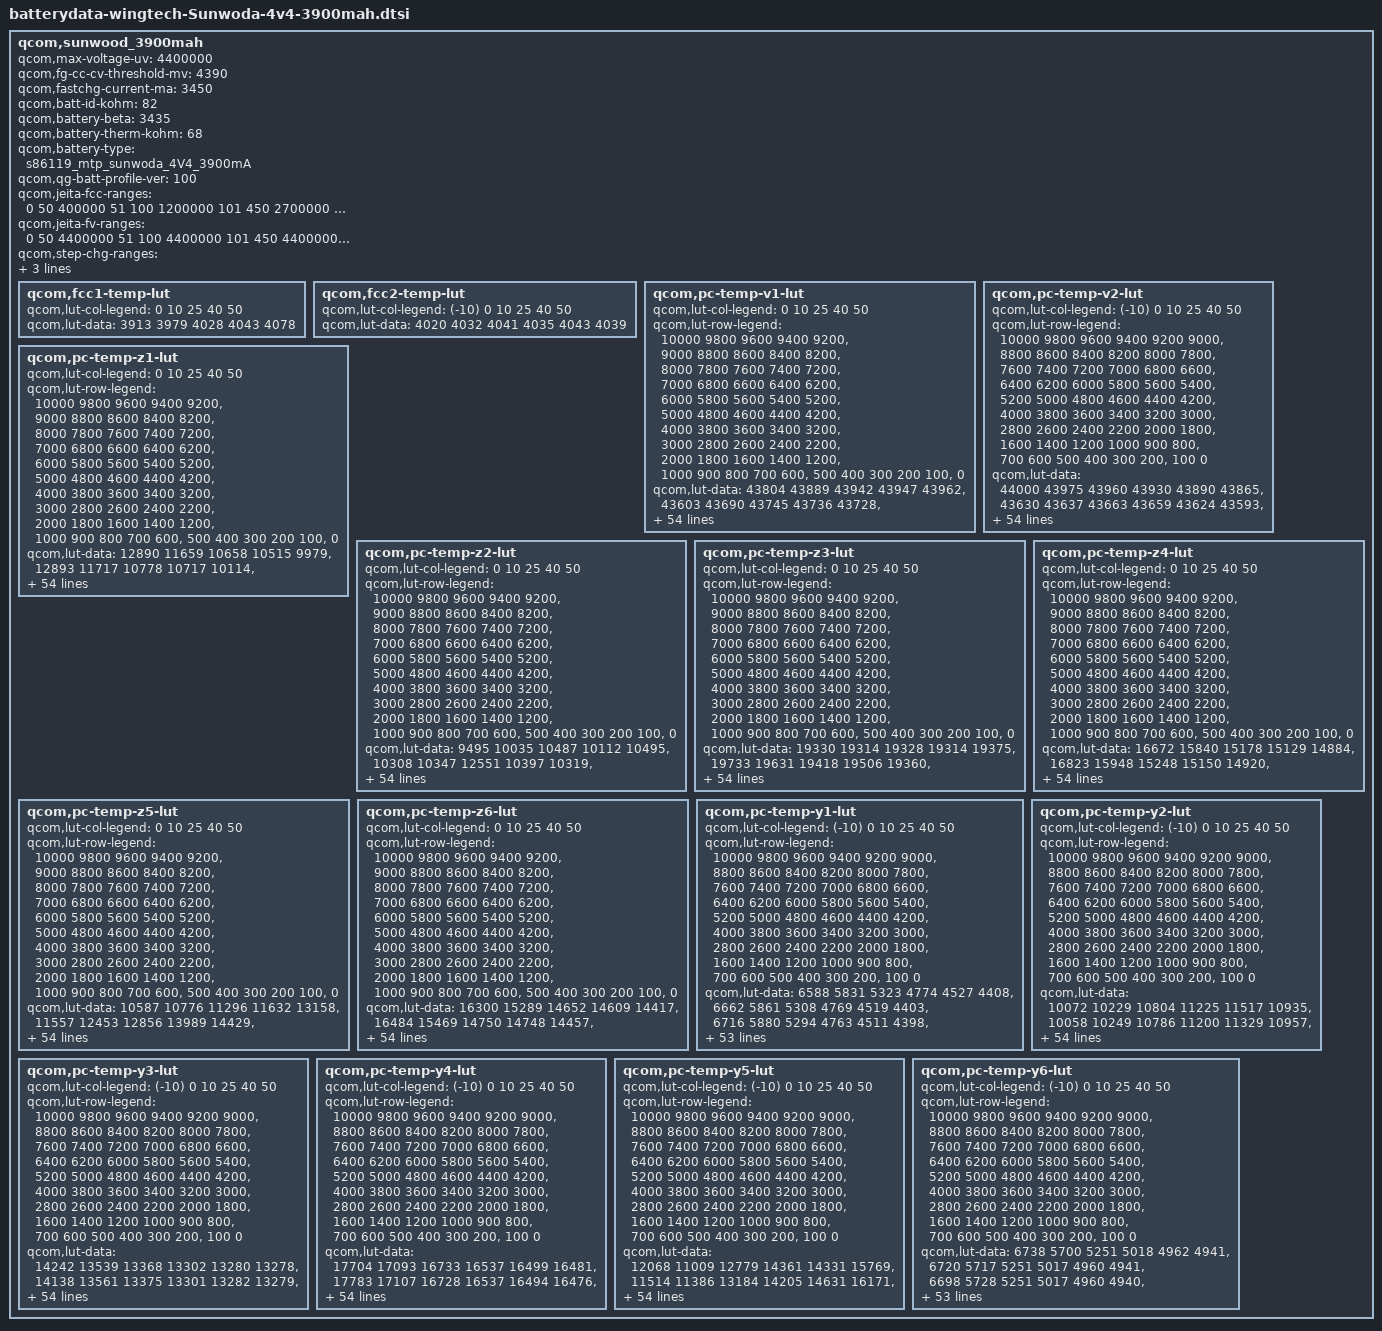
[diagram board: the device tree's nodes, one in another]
/* Copyright (c) 2018, The Linux Foundation. All rights reserved.
 *
 * This program is free software; you can redistribute it and/or modify
 * it under the terms of the GNU General Public License version 2 and
 * only version 2 as published by the Free Software Foundation.
 *
 * This program is distributed in the hope that it will be useful,
 * but WITHOUT ANY WARRANTY; without even the implied warranty of
 * MERCHANTABILITY or FITNESS FOR A PARTICULAR PURPOSE.  See the
 * GNU General Public License for more details.
 */

qcom,sunwood_3900mah {
	/* Sunwood_wConn_3450mAh_Fresh_averaged_MasterSlave_Feb7th2018 */
	qcom,max-voltage-uv = <4400000>;
	qcom,fg-cc-cv-threshold-mv = <4390>;
	qcom,fastchg-current-ma = <3450>;
	qcom,batt-id-kohm = <82>;
	qcom,battery-beta = <3435>;
	qcom,battery-therm-kohm = <68>;
	qcom,battery-type =
		"s86119_mtp_sunwoda_4V4_3900mA";
	qcom,qg-batt-profile-ver = <100>;
	//+Bug 439935 gudi.wt,MODIFIY,20190628,S86119AA1 set follow to batt spec
	qcom,jeita-fcc-ranges = <0   50  400000
				51   100 1200000
				101  450 2700000
				451  600 1400000>;
	qcom,jeita-fv-ranges = <0   50   4400000
				51  100  4400000
				101 450  4400000
				451 600  4100000>;
	qcom,step-chg-ranges = <3600000  4250000  2700000
				4251000  4300000  2700000
				4301000  4400000  2700000>;

	/* COOL = 5 DegC, WARM = 45 DegC */
qcom,jeita-soft-thresholds = <0x7001 0x0101>;
	/* COLD = 0 DegC, HOT = 55 DegC */
	qcom,jeita-hard-thresholds = <0x7001 0x0101>;
	//-Bug 439935 gudi.wt,MODIFIY,20190628,S86119AA1 set follow to batt spec
	qcom,fcc1-temp-lut {
		qcom,lut-col-legend = <0 10 25 40 50>;
		qcom,lut-data = <3913 3979 4028 4043 4078>;
	};

	qcom,fcc2-temp-lut {
		qcom,lut-col-legend = <(-10) 0 10 25 40 50>;
		qcom,lut-data = <4020 4032 4041 4035 4043 4039>;
	};

	qcom,pc-temp-v1-lut {
		qcom,lut-col-legend = <0 10 25 40 50>;
		qcom,lut-row-legend = <10000 9800 9600 9400 9200>,
			<9000 8800 8600 8400 8200>,
			<8000 7800 7600 7400 7200>,
			<7000 6800 6600 6400 6200>,
			<6000 5800 5600 5400 5200>,
			<5000 4800 4600 4400 4200>,
			<4000 3800 3600 3400 3200>,
			<3000 2800 2600 2400 2200>,
			<2000 1800 1600 1400 1200>,
			<1000 900 800 700 600>,
			<500 400 300 200 100>,
			<0>;
		qcom,lut-data = <43804 43889 43942 43947 43962>,
			<43603 43690 43745 43736 43728>,
			<43344 43446 43527 43514 43501>,
			<43096 43195 43287 43270 43277>,
			<42867 42953 43044 43027 43050>,
			<42638 42718 42807 42799 42820>,
			<42403 42486 42571 42573 42589>,
			<42165 42255 42337 42339 42357>,
			<41936 42026 42106 42096 42126>,
			<41715 41802 41877 41861 41894>,
			<41502 41581 41650 41639 41666>,
			<41306 41370 41428 41423 41440>,
			<41119 41178 41217 41205 41218>,
			<40914 40987 41016 40989 40997>,
			<40682 40772 40811 40780 40784>,
			<40450 40540 40597 40581 40586>,
			<40227 40326 40390 40386 40398>,
			<40015 40130 40199 40187 40216>,
			<39843 39953 40020 39994 40039>,
			<39705 39802 39855 39830 39866>,
			<39578 39666 39712 39700 39710>,
			<39452 39525 39549 39557 39548>,
			<39330 39382 39316 39346 39322>,
			<39212 39226 39064 39100 39035>,
			<39097 39025 38867 38911 38836>,
			<38986 38813 38700 38757 38718>,
			<38877 38665 38580 38638 38622>,
			<38770 38556 38504 38546 38534>,
			<38675 38473 38442 38468 38454>,
			<38585 38411 38378 38387 38371>,
			<38507 38362 38319 38309 38284>,
			<38436 38317 38262 38240 38203>,
			<38373 38276 38207 38178 38131>,
			<38323 38238 38154 38125 38064>,
			<38286 38202 38103 38085 38001>,
			<38249 38165 38054 38048 37942>,
			<38206 38126 38009 38000 37886>,
			<38160 38086 37970 37927 37837>,
			<38100 38030 37919 37850 37779>,
			<38024 37940 37829 37778 37685>,
			<37931 37828 37711 37694 37560>,
			<37806 37706 37587 37579 37430>,
			<37657 37565 37448 37427 37289>,
			<37492 37401 37292 37264 37137>,
			<37352 37255 37154 37116 37002>,
			<37253 37168 37071 37041 36923>,
			<37216 37139 37049 37035 36902>,
			<37192 37123 37034 36963 36889>,
			<37166 37102 37014 36925 36867>,
			<37111 37046 36947 36847 36771>,
			<36858 36781 36672 36591 36471>,
			<36406 36333 36224 36120 36014>,
			<35810 35740 35634 35577 35422>,
			<34996 34926 34823 34756 34610>,
			<33712 33646 33553 33486 33343>,
			<30000 30000 30000 30000 30000>;
	};

	qcom,pc-temp-v2-lut {
		qcom,lut-col-legend = <(-10) 0 10 25 40 50>;
		qcom,lut-row-legend = <10000 9800 9600 9400 9200 9000>,
			<8800 8600 8400 8200 8000 7800>,
			<7600 7400 7200 7000 6800 6600>,
			<6400 6200 6000 5800 5600 5400>,
			<5200 5000 4800 4600 4400 4200>,
			<4000 3800 3600 3400 3200 3000>,
			<2800 2600 2400 2200 2000 1800>,
			<1600 1400 1200 1000 900 800>,
			<700 600 500 400 300 200>,
			<100 0>;
		qcom,lut-data = <44000 43975 43960 43930 43890 43865>,
			<43630 43637 43663 43659 43624 43593>,
			<43288 43327 43384 43399 43369 43332>,
			<42974 43047 43124 43152 43125 43087>,
			<42683 42796 42881 42918 42894 42855>,
			<42428 42549 42642 42685 42663 42624>,
			<42222 42300 42403 42450 42429 42390>,
			<42020 42059 42167 42217 42195 42158>,
			<41752 41837 41939 41987 41964 41928>,
			<41441 41627 41716 41759 41735 41700>,
			<41234 41413 41493 41534 41510 41476>,
			<41127 41189 41271 41310 41289 41255>,
			<41011 40980 41059 41093 41073 41038>,
			<40771 40820 40875 40892 40866 40830>,
			<40431 40671 40698 40696 40663 40625>,
			<40110 40439 40485 40490 40459 40426>,
			<39785 40073 40232 40272 40254 40230>,
			<39519 39759 39987 40071 40063 40045>,
			<39344 39563 39760 39907 39896 39876>,
			<39197 39396 39546 39746 39732 39710>,
			<39039 39220 39352 39544 39546 39525>,
			<38876 39044 39171 39309 39344 39325>,
			<38721 38881 39001 39095 39141 39126>,
			<38565 38735 38837 38902 38928 38918>,
			<38427 38595 38687 38733 38741 38733>,
			<38324 38453 38556 38598 38605 38598>,
			<38240 38313 38437 38484 38493 38486>,
			<38166 38199 38329 38379 38388 38381>,
			<38098 38104 38230 38282 38291 38285>,
			<38034 38026 38137 38192 38204 38196>,
			<37974 37968 38048 38110 38133 38116>,
			<37916 37919 37967 38035 38066 38041>,
			<37856 37871 37896 37967 37992 37973>,
			<37794 37825 37834 37905 37913 37911>,
			<37733 37779 37783 37843 37831 37837>,
			<37674 37732 37744 37779 37743 37737>,
			<37614 37683 37706 37714 37654 37628>,
			<37552 37629 37665 37645 37565 37526>,
			<37487 37569 37620 37572 37476 37425>,
			<37424 37500 37558 37493 37406 37335>,
			<37364 37418 37468 37410 37351 37256>,
			<37300 37320 37363 37312 37258 37159>,
			<37228 37203 37239 37191 37134 37037>,
			<37150 37089 37086 37045 37041 36898>,
			<37052 36975 36951 36916 36850 36788>,
			<36930 36886 36891 36881 36819 36765>,
			<36870 36848 36867 36866 36824 36749>,
			<36798 36807 36843 36848 36826 36725>,
			<36714 36748 36806 36811 36786 36681>,
			<36563 36643 36704 36701 36691 36527>,
			<36321 36392 36416 36368 36357 36144>,
			<35904 35926 35908 35854 35853 35618>,
			<35280 35284 35225 35183 35177 34930>,
			<34376 34371 34278 34261 34288 33990>,
			<32889 32909 32949 32942 32763 32685>,
			<28713 29353 28070 28143 30475 28452>;
	};

	qcom,pc-temp-z1-lut {
		qcom,lut-col-legend = <0 10 25 40 50>;
		qcom,lut-row-legend = <10000 9800 9600 9400 9200>,
			<9000 8800 8600 8400 8200>,
			<8000 7800 7600 7400 7200>,
			<7000 6800 6600 6400 6200>,
			<6000 5800 5600 5400 5200>,
			<5000 4800 4600 4400 4200>,
			<4000 3800 3600 3400 3200>,
			<3000 2800 2600 2400 2200>,
			<2000 1800 1600 1400 1200>,
			<1000 900 800 700 600>,
			<500 400 300 200 100>,
			<0>;
		qcom,lut-data = <12890 11659 10658 10515 9979>,
			<12893 11717 10778 10717 10114>,
			<12969 11729 10779 10629 10129>,
			<13012 11750 10769 10666 10125>,
			<13011 11754 10760 10692 10125>,
			<12997 11754 10754 10656 10123>,
			<13003 11754 10748 10581 10121>,
			<13023 11748 10740 10528 10119>,
			<13026 11741 10730 10482 10116>,
			<13005 11742 10722 10464 10114>,
			<12985 11741 10719 10550 10120>,
			<12981 11738 10717 10657 10147>,
			<12979 11732 10715 10638 10159>,
			<12971 11725 10712 10540 10158>,
			<12930 11710 10712 10470 10156>,
			<12887 11682 10710 10424 10156>,
			<12865 11672 10708 10397 10156>,
			<12845 11670 10708 10448 10160>,
			<12838 11668 10707 10558 10180>,
			<12819 11664 10708 10583 10194>,
			<12799 11660 10709 10567 10192>,
			<12769 11659 10711 10556 10188>,
			<12720 11658 10715 10594 10180>,
			<12706 11658 10723 10648 10167>,
			<12708 11667 10730 10656 10163>,
			<12708 11682 10737 10657 10170>,
			<12701 11689 10742 10659 10177>,
			<12689 11695 10745 10664 10178>,
			<12686 11696 10747 10670 10178>,
			<12695 11690 10748 10615 10187>,
			<12702 11684 10749 10472 10235>,
			<12709 11680 10750 10433 10263>,
			<12719 11676 10756 10488 10260>,
			<12726 11674 10762 10533 10250>,
			<12735 11677 10766 10501 10231>,
			<12741 11683 10770 10444 10199>,
			<12742 11694 10777 10437 10179>,
			<12741 11715 10789 10457 10167>,
			<12741 11729 10797 10469 10161>,
			<12745 11737 10800 10446 10163>,
			<12753 11742 10802 10416 10166>,
			<12775 11744 10804 10487 10169>,
			<12795 11745 10807 10666 10171>,
			<12779 11735 10817 10678 10174>,
			<12752 11722 10827 10680 10178>,
			<12760 11713 10820 10541 10180>,
			<12745 11686 10811 10532 10179>,
			<12718 11690 10813 10562 10180>,
			<12706 11701 10818 10566 10180>,
			<12691 11724 10829 10557 10183>,
			<12721 11711 10837 10550 10188>,
			<12692 11732 10843 10671 10191>,
			<12739 11727 10854 10503 10199>,
			<12710 11743 10881 10618 10208>,
			<12710 11743 10881 10618 10208>,
			<12710 11743 10881 10618 10208>;
	};

	qcom,pc-temp-z2-lut {
		qcom,lut-col-legend = <0 10 25 40 50>;
		qcom,lut-row-legend = <10000 9800 9600 9400 9200>,
			<9000 8800 8600 8400 8200>,
			<8000 7800 7600 7400 7200>,
			<7000 6800 6600 6400 6200>,
			<6000 5800 5600 5400 5200>,
			<5000 4800 4600 4400 4200>,
			<4000 3800 3600 3400 3200>,
			<3000 2800 2600 2400 2200>,
			<2000 1800 1600 1400 1200>,
			<1000 900 800 700 600>,
			<500 400 300 200 100>,
			<0>;
		qcom,lut-data = <9495 10035 10487 10112 10495>,
			<10308 10347 12551 10397 10319>,
			<10080 10276 11212 10496 10600>,
			<10128 10183 10600 10416 10618>,
			<10293 10156 10377 10340 10538>,
			<10408 10148 10347 10325 10492>,
			<10358 10145 10323 10318 10466>,
			<10203 10156 10327 10334 10450>,
			<10131 10170 10357 10406 10442>,
			<10119 10169 10377 10451 10438>,
			<10115 10161 10382 10419 10448>,
			<10121 10157 10386 10377 10477>,
			<10134 10174 10395 10396 10494>,
			<10141 10194 10412 10461 10510>,
			<10143 10193 10427 10486 10516>,
			<10144 10182 10439 10440 10477>,
			<10142 10180 10452 10394 10416>,
			<10138 10220 10507 10394 10400>,
			<10144 10260 10589 10409 10407>,
			<10191 10264 10590 10440 10412>,
			<10241 10262 10508 10508 10379>,
			<10269 10261 10465 10561 10343>,
			<10290 10265 10495 10530 10444>,
			<10293 10269 10537 10475 10707>,
			<10282 10277 10540 10479 10791>,
			<10270 10286 10516 10485 10626>,
			<10263 10291 10499 10474 10468>,
			<10257 10296 10486 10456 10426>,
			<10254 10298 10477 10451 10406>,
			<10251 10298 10494 10523 10465>,
			<10250 10298 10539 10670 10678>,
			<10255 10301 10557 10715 10789>,
			<10264 10310 10553 10638 10696>,
			<10270 10318 10545 10557 10582>,
			<10274 10325 10534 10537 10565>,
			<10278 10331 10519 10532 10573>,
			<10282 10339 10517 10546 10566>,
			<10287 10348 10520 10579 10535>,
			<10296 10357 10525 10618 10518>,
			<10321 10365 10563 10665 10629>,
			<10354 10376 10611 10717 10805>,
			<10388 10393 10621 10850 10836>,
			<10437 10421 10624 11094 10837>,
			<10583 10469 10636 10972 10791>,
			<10449 10653 10719 10888 10648>,
			<10080 11048 10884 11107 10580>,
			<10064 11106 10904 11077 10579>,
			<10090 10835 10932 10730 10535>,
			<9980 10847 10934 10611 10593>,
			<10096 11117 11002 10666 10674>,
			<10053 11065 11156 10696 10571>,
			<10041 10878 11080 10799 10444>,
			<9862 10677 11253 11604 10412>,
			<9733 10569 11037 10970 10252>,
			<9733 10569 11037 10970 10252>,
			<9733 10569 11037 10970 10252>;
	};

	qcom,pc-temp-z3-lut {
		qcom,lut-col-legend = <0 10 25 40 50>;
		qcom,lut-row-legend = <10000 9800 9600 9400 9200>,
			<9000 8800 8600 8400 8200>,
			<8000 7800 7600 7400 7200>,
			<7000 6800 6600 6400 6200>,
			<6000 5800 5600 5400 5200>,
			<5000 4800 4600 4400 4200>,
			<4000 3800 3600 3400 3200>,
			<3000 2800 2600 2400 2200>,
			<2000 1800 1600 1400 1200>,
			<1000 900 800 700 600>,
			<500 400 300 200 100>,
			<0>;
		qcom,lut-data = <19330 19314 19328 19314 19375>,
			<19733 19631 19418 19506 19360>,
			<19955 19713 19488 19511 19420>,
			<20034 19832 19564 19537 19460>,
			<20032 19858 19606 19551 19473>,
			<20013 19862 19613 19561 19474>,
			<20011 19862 19617 19567 19459>,
			<20014 19859 19613 19564 19443>,
			<20019 19854 19593 19547 19432>,
			<20025 19849 19575 19533 19423>,
			<20030 19843 19561 19554 19421>,
			<20024 19835 19546 19581 19422>,
			<20011 19811 19531 19567 19425>,
			<20006 19790 19516 19517 19433>,
			<20013 19792 19512 19485 19438>,
			<20023 19804 19512 19464 19423>,
			<20047 19805 19513 19449 19392>,
			<20083 19759 19514 19460 19382>,
			<20083 19714 19514 19487 19381>,
			<20013 19712 19511 19486 19382>,
			<19955 19716 19498 19437 19374>,
			<19957 19720 19494 19404 19365>,
			<19966 19726 19515 19442 19370>,
			<19976 19735 19542 19502 19390>,
			<19994 19763 19545 19508 19397>,
			<20013 19800 19538 19488 19384>,
			<20030 19806 19529 19472 19367>,
			<20046 19800 19516 19463 19351>,
			<20053 19793 19503 19457 19334>,
			<20061 19786 19496 19451 19335>,
			<20064 19776 19490 19447 19361>,
			<20062 19765 19490 19448 19382>,
			<20058 19752 19499 19453 19394>,
			<20048 19740 19508 19455 19402>,
			<20016 19732 19513 19446 19399>,
			<19980 19724 19517 19431 19388>,
			<19959 19717 19516 19427 19378>,
			<19940 19710 19506 19430 19361>,
			<19915 19704 19497 19429 19350>,
			<19879 19700 19493 19408 19354>,
			<19840 19694 19489 19380 19361>,
			<19804 19681 19485 19372 19366>,
			<19762 19656 19482 19369 19371>,
			<19701 19631 19472 19357 19368>,
			<19503 19569 19446 19337 19354>,
			<19347 19446 19408 19324 19341>,
			<19351 19427 19400 19323 19341>,
			<19343 19337 19377 19362 19332>,
			<19337 19325 19386 19366 19320>,
			<19339 19334 19365 19353 19321>,
			<19346 19362 19351 19356 19325>,
			<19352 19340 19326 19319 19334>,
			<19364 19339 19325 19290 19337>,
			<19363 19338 19320 19429 19344>,
			<19363 19338 19320 19429 19344>,
			<19363 19338 19320 19429 19344>;
	};

	qcom,pc-temp-z4-lut {
		qcom,lut-col-legend = <0 10 25 40 50>;
		qcom,lut-row-legend = <10000 9800 9600 9400 9200>,
			<9000 8800 8600 8400 8200>,
			<8000 7800 7600 7400 7200>,
			<7000 6800 6600 6400 6200>,
			<6000 5800 5600 5400 5200>,
			<5000 4800 4600 4400 4200>,
			<4000 3800 3600 3400 3200>,
			<3000 2800 2600 2400 2200>,
			<2000 1800 1600 1400 1200>,
			<1000 900 800 700 600>,
			<500 400 300 200 100>,
			<0>;
		qcom,lut-data = <16672 15840 15178 15129 14884>,
			<16823 15948 15248 15150 14920>,
			<16887 15946 15372 15199 14921>,
			<16873 15784 15271 15211 14952>,
			<16669 15643 15156 15200 14889>,
			<16420 15505 15085 15117 14845>,
			<16252 15387 15025 14981 14817>,
			<16105 15293 14971 14893 14799>,
			<15977 15215 14918 14829 14791>,
			<15864 15155 14884 14800 14785>,
			<15765 15107 14870 14795 14782>,
			<15676 15064 14859 14790 14783>,
			<15597 15022 14847 14782 14782>,
			<15545 14983 14836 14770 14755>,
			<15514 14942 14824 14763 14728>,
			<15485 14901 14814 14774 14727>,
			<15441 14892 14802 14784 14732>,
			<15394 14925 14778 14773 14729>,
			<15380 14955 14750 14747 14715>,
			<15391 14937 14739 14741 14706>,
			<15398 14888 14730 14759 14709>,
			<15355 14855 14731 14771 14720>,
			<15266 14831 14762 14783 14751>,
			<15193 14819 14812 14814 14819>,
			<15129 14834 14853 14840 14854>,
			<15075 14865 14894 14883 14866>,
			<15036 14883 14909 14902 14872>,
			<15003 14895 14901 14900 14876>,
			<14982 14900 14887 14894 14876>,
			<14964 14894 14873 14869 14865>,
			<14950 14882 14856 14815 14830>,
			<14934 14871 14835 14786 14794>,
			<14919 14860 14805 14770 14759>,
			<14916 14850 14779 14760 14730>,
			<14920 14839 14760 14752 14725>,
			<14923 14828 14747 14740 14723>,
			<14920 14818 14744 14736 14723>,
			<14914 14807 14743 14736 14724>,
			<14914 14803 14743 14739 14727>,
			<14920 14801 14755 14750 14733>,
			<14928 14801 14769 14767 14741>,
			<14939 14802 14768 14802 14739>,
			<14948 14803 14760 14863 14730>,
			<14953 14799 14760 14867 14733>,
			<14999 14787 14753 14859 14737>,
			<15054 14806 14721 14770 14705>,
			<15047 14821 14718 14737 14690>,
			<15048 14916 14725 14721 14676>,
			<15049 14924 14705 14714 14665>,
			<15038 14906 14733 14731 14675>,
			<15033 14891 14777 14738 14708>,
			<15042 14924 14815 14841 14704>,
			<15048 14934 14820 14789 14704>,
			<15062 14941 14833 14669 14699>,
			<15062 14941 14833 14669 14699>,
			<15062 14941 14833 14669 14699>;
	};

	qcom,pc-temp-z5-lut {
		qcom,lut-col-legend = <0 10 25 40 50>;
		qcom,lut-row-legend = <10000 9800 9600 9400 9200>,
			<9000 8800 8600 8400 8200>,
			<8000 7800 7600 7400 7200>,
			<7000 6800 6600 6400 6200>,
			<6000 5800 5600 5400 5200>,
			<5000 4800 4600 4400 4200>,
			<4000 3800 3600 3400 3200>,
			<3000 2800 2600 2400 2200>,
			<2000 1800 1600 1400 1200>,
			<1000 900 800 700 600>,
			<500 400 300 200 100>,
			<0>;
		qcom,lut-data = <10587 10776 11296 11632 13158>,
			<11557 12453 12856 13989 14429>,
			<12201 12973 13438 15014 17050>,
			<12487 13849 14567 15157 17471>,
			<12525 14217 15511 15379 18469>,
			<12534 14362 15901 15600 18738>,
			<12704 14527 16184 15862 18715>,
			<13051 14810 16537 16867 18670>,
			<13332 15152 17055 21283 18429>,
			<13539 15474 17393 23666 18072>,
			<13715 15787 17487 21718 17863>,
			<13867 16092 17495 19349 17621>,
			<13996 16342 17450 20053 17750>,
			<14077 16665 17373 23155 25015>,
			<14173 17918 17376 24243 32470>,
			<14300 20371 17854 20486 29087>,
			<14712 21073 18514 16914 20734>,
			<15350 18668 19963 19535 18814>,
			<15441 16423 22031 25525 20978>,
			<14758 16703 22404 26587 22519>,
			<14203 17876 22860 21327 20979>,
			<14418 19355 24567 18065 19028>,
			<15033 21472 35943 23132 22881>,
			<15771 24683 50303 31360 33796>,
			<16854 33966 50583 32438 37412>,
			<18232 46013 43368 27964 30081>,
			<20180 47756 36443 23640 21992>,
			<22509 43906 30699 20529 18120>,
			<23871 39708 26129 18242 15346>,
			<25269 36373 23520 19241 15037>,
			<26413 33276 21601 22353 16000>,
			<27401 30856 21260 23599 17363>,
			<28522 28766 22556 24391 20644>,
			<28422 27585 24427 25228 24256>,
			<25776 26947 27434 24973 25532>,
			<23402 26556 30873 24241 26291>,
			<22725 26550 31260 25296 26401>,
			<22263 26644 29870 30990 24057>,
			<21666 26835 28435 33713 22098>,
			<20621 27774 27362 27413 21476>,
			<19580 28617 26405 19285 20620>,
			<18808 27257 25714 17079 20806>,
			<18091 24449 25107 16239 21335>,
			<17251 23644 23197 16037 20291>,
			<14739 22445 21902 16069 18157>,
			<12709 17021 21067 16240 18025>,
			<12736 15882 19560 15299 18625>,
			<12561 12929 16849 22800 18252>,
			<12459 12534 17958 24477 18272>,
			<12554 12860 15963 22339 17537>,
			<12792 13701 14575 19064 14623>,
			<12731 12904 13162 13811 14684>,
			<12687 12704 12902 12151 14462>,
			<12490 12547 12555 65535 14658>,
			<12490 12547 12555 65535 14658>,
			<12490 12547 12555 65535 14658>;
	};

	qcom,pc-temp-z6-lut {
		qcom,lut-col-legend = <0 10 25 40 50>;
		qcom,lut-row-legend = <10000 9800 9600 9400 9200>,
			<9000 8800 8600 8400 8200>,
			<8000 7800 7600 7400 7200>,
			<7000 6800 6600 6400 6200>,
			<6000 5800 5600 5400 5200>,
			<5000 4800 4600 4400 4200>,
			<4000 3800 3600 3400 3200>,
			<3000 2800 2600 2400 2200>,
			<2000 1800 1600 1400 1200>,
			<1000 900 800 700 600>,
			<500 400 300 200 100>,
			<0>;
		qcom,lut-data = <16300 15289 14652 14609 14417>,
			<16484 15469 14750 14748 14457>,
			<16576 15476 14832 14746 14490>,
			<16589 15462 14820 14771 14520>,
			<16480 15433 14801 14783 14504>,
			<16337 15359 14779 14745 14487>,
			<16239 15289 14748 14674 14467>,
			<16151 15238 14718 14621 14451>,
			<16079 15196 14684 14576 14440>,
			<16021 15163 14658 14554 14433>,
			<15971 15137 14643 14579 14431>,
			<15919 15110 14631 14611 14438>,
			<15866 15075 14618 14596 14439>,
			<15829 15043 14605 14544 14432>,
			<15803 15024 14597 14513 14422>,
			<15784 15009 14592 14499 14411>,
			<15774 14999 14587 14491 14397>,
			<15765 14989 14577 14499 14391>,
			<15751 14979 14566 14522 14387>,
			<15722 14965 14557 14523 14385>,
			<15687 14948 14548 14502 14384>,
			<15648 14938 14544 14488 14382>,
			<15606 14933 14568 14519 14395>,
			<15583 14930 14607 14576 14435>,
			<15572 14949 14626 14594 14450>,
			<15562 14984 14640 14600 14448>,
			<15550 14997 14644 14601 14445>,
			<15539 15001 14636 14598 14439>,
			<15535 15003 14623 14592 14430>,
			<15535 14999 14613 14568 14427>,
			<15535 14990 14604 14513 14433>,
			<15528 14981 14596 14494 14435>,
			<15517 14967 14588 14500 14427>,
			<15505 14956 14582 14505 14416>,
			<15493 14949 14579 14491 14406>,
			<15482 14943 14576 14467 14396>,
			<15475 14936 14573 14462 14387>,
			<15468 14928 14570 14466 14375>,
			<15460 14925 14568 14468 14369>,
			<15450 14927 14571 14458 14374>,
			<15439 14929 14575 14446 14382>,
			<15429 14926 14575 14470 14383>,
			<15416 14918 14571 14533 14383>,
			<15389 14908 14568 14533 14382>,
			<15306 14872 14555 14519 14378>,
			<15249 14823 14522 14441 14357>,
			<15242 14816 14513 14425 14351>,
			<15242 14812 14506 14444 14340>,
			<15245 14814 14502 14442 14328>,
			<15241 14810 14506 14443 14334>,
			<15255 14819 14520 14446 14352>,
			<15258 14831 14525 14499 14357>,
			<15284 14845 14529 14424 14360>,
			<15296 14857 14540 14471 14364>,
			<15296 14857 14540 14471 14364>,
			<15296 14857 14540 14471 14364>;
	};

	qcom,pc-temp-y1-lut {
		qcom,lut-col-legend = <(-10) 0 10 25 40 50>;
		qcom,lut-row-legend = <10000 9800 9600 9400 9200 9000>,
			<8800 8600 8400 8200 8000 7800>,
			<7600 7400 7200 7000 6800 6600>,
			<6400 6200 6000 5800 5600 5400>,
			<5200 5000 4800 4600 4400 4200>,
			<4000 3800 3600 3400 3200 3000>,
			<2800 2600 2400 2200 2000 1800>,
			<1600 1400 1200 1000 900 800>,
			<700 600 500 400 300 200>,
			<100 0>;
		qcom,lut-data = <6588 5831 5323 4774 4527 4408>,
			<6662 5861 5308 4769 4519 4403>,
			<6716 5880 5294 4763 4511 4398>,
			<6751 5889 5283 4758 4505 4394>,
			<6773 5891 5276 4752 4500 4390>,
			<6783 5887 5275 4747 4497 4387>,
			<6770 5869 5279 4742 4496 4384>,
			<6752 5851 5284 4737 4496 4382>,
			<6751 5862 5276 4732 4492 4382>,
			<6751 5893 5256 4727 4485 4381>,
			<6752 5902 5246 4725 4480 4381>,
			<6756 5890 5242 4722 4478 4381>,
			<6761 5879 5240 4721 4476 4381>,
			<6765 5884 5236 4719 4475 4380>,
			<6768 5898 5231 4717 4476 4378>,
			<6770 5895 5231 4717 4474 4378>,
			<6778 5876 5238 4719 4471 4378>,
			<6779 5865 5242 4720 4469 4378>,
			<6767 5874 5241 4718 4469 4379>,
			<6754 5889 5238 4715 4470 4380>,
			<6753 5899 5243 4718 4470 4380>,
			<6758 5908 5258 4729 4470 4380>,
			<6760 5910 5263 4734 4470 4380>,
			<6740 5896 5264 4733 4472 4383>,
			<6716 5881 5266 4732 4473 4385>,
			<6712 5874 5266 4734 4479 4386>,
			<6716 5868 5265 4739 4491 4387>,
			<6720 5864 5265 4744 4502 4388>,
			<6722 5859 5265 4750 4515 4390>,
			<6724 5856 5267 4755 4522 4392>,
			<6724 5866 5271 4757 4522 4393>,
			<6724 5882 5278 4759 4521 4393>,
			<6723 5883 5287 4764 4518 4395>,
			<6712 5882 5296 4772 4515 4398>,
			<6698 5880 5299 4777 4518 4402>,
			<6673 5870 5290 4779 4559 4406>,
			<6644 5861 5281 4781 4601 4410>,
			<6646 5866 5286 4788 4616 4412>,
			<6665 5876 5298 4799 4627 4414>,
			<6687 5873 5304 4801 4620 4415>,
			<6715 5844 5300 4796 4574 4415>,
			<6729 5839 5302 4798 4570 4417>,
			<6700 5863 5307 4809 4595 4420>,
			<6674 5893 5293 4812 4614 4421>,
			<6685 5884 5304 4813 4654 4422>,
			<6732 5838 5306 4814 4648 4424>,
			<6760 5868 5314 4822 4645 4426>,
			<6726 5861 5311 4815 4674 4426>,
			<6690 5858 5298 4818 4687 4429>,
			<6706 5849 5296 4825 4681 4426>,
			<6718 5881 5301 4827 4642 4426>,
			<6701 5859 5318 4828 4670 4431>,
			<6763 5856 5347 4840 4676 4434>,
			<6900 5903 5352 4853 4687 4440>,
			<6900 5903 5352 4853 4687 4440>,
			<6900 5903 5352 4853 4687 4440>;
	};

	qcom,pc-temp-y2-lut {
		qcom,lut-col-legend = <(-10) 0 10 25 40 50>;
		qcom,lut-row-legend = <10000 9800 9600 9400 9200 9000>,
			<8800 8600 8400 8200 8000 7800>,
			<7600 7400 7200 7000 6800 6600>,
			<6400 6200 6000 5800 5600 5400>,
			<5200 5000 4800 4600 4400 4200>,
			<4000 3800 3600 3400 3200 3000>,
			<2800 2600 2400 2200 2000 1800>,
			<1600 1400 1200 1000 900 800>,
			<700 600 500 400 300 200>,
			<100 0>;
		qcom,lut-data = <10072 10229 10804 11225 11517 10935>,
			<10058 10249 10786 11200 11329 10957>,
			<10059 10268 10766 11166 11164 10957>,
			<10072 10286 10746 11132 11035 10945>,
			<10093 10304 10730 11104 10953 10932>,
			<10120 10321 10722 11092 10932 10927>,
			<10152 10340 10718 11087 10981 10907>,
			<10197 10354 10716 11087 11040 10886>,
			<10310 10348 10720 11096 11071 10886>,
			<10499 10330 10730 11110 11110 10892>,
			<10555 10338 10736 11117 11138 10915>,
			<10495 10486 10740 11125 11161 10998>,
			<10444 10617 10744 11131 11175 11067>,
			<10499 10635 10758 11124 11178 11072>,
			<10607 10640 10784 11115 11184 11061>,
			<10546 10643 10816 11127 11206 11075>,
			<10022 10651 10867 11172 11263 11154>,
			<9681 10665 10895 11208 11319 11208>,
			<9676 10713 10900 11234 11373 11251>,
			<9673 10787 10903 11254 11422 11316>,
			<9671 10854 10918 11240 11451 11409>,
			<9670 10924 10953 11194 11475 11539>,
			<9668 10965 10990 11179 11472 11565>,
			<9666 10997 11029 11215 11370 11350>,
			<9665 11016 11069 11261 11285 11160>,
			<9664 11007 11110 11293 11286 11179>,
			<9663 10986 11149 11326 11292 11229>,
			<9662 10986 11177 11349 11344 11245>,
			<9661 11029 11199 11386 11569 11228>,
			<9661 11058 11208 11409 11698 11222>,
			<9660 10836 11204 11398 11575 11273>,
			<9660 10458 11195 11382 11422 11350>,
			<9659 10256 11190 11380 11488 11408>,
			<9659 9881 11187 11391 11716 11472>,
			<9658 9705 11179 11392 11778 11489>,
			<9658 9692 11139 11371 11440 11330>,
			<9658 9684 11088 11348 11115 11172>,
			<9657 9677 11050 11343 11087 11188>,
			<9657 9671 11016 11346 11111 11237>,
			<9657 9667 10986 11334 11253 11245>,
			<9657 9665 10962 11257 11890 11219>,
			<9656 9663 10931 11237 11755 11267>,
			<9656 9661 10884 11319 11191 11369>,
			<9656 9660 10818 11242 11245 11115>,
			<9656 9661 10778 11258 11083 11051>,
			<9656 9659 10718 11222 10934 11008>,
			<9656 9658 10675 11211 10935 10968>,
			<9656 9657 10622 11205 11004 11005>,
			<9655 9656 10617 11177 10910 10942>,
			<9655 9656 10579 11072 10987 10874>,
			<9655 9655 10522 11057 10955 10901>,
			<9654 9655 10278 10998 11030 10904>,
			<9653 9654 9828 10976 10842 10772>,
			<9651 9653 9692 10834 10771 10651>,
			<9651 9653 9692 10834 10771 10651>,
			<9651 9653 9692 10834 10771 10651>;
	};

	qcom,pc-temp-y3-lut {
		qcom,lut-col-legend = <(-10) 0 10 25 40 50>;
		qcom,lut-row-legend = <10000 9800 9600 9400 9200 9000>,
			<8800 8600 8400 8200 8000 7800>,
			<7600 7400 7200 7000 6800 6600>,
			<6400 6200 6000 5800 5600 5400>,
			<5200 5000 4800 4600 4400 4200>,
			<4000 3800 3600 3400 3200 3000>,
			<2800 2600 2400 2200 2000 1800>,
			<1600 1400 1200 1000 900 800>,
			<700 600 500 400 300 200>,
			<100 0>;
		qcom,lut-data = <14242 13539 13368 13302 13280 13278>,
			<14138 13561 13375 13301 13282 13279>,
			<14056 13579 13381 13301 13283 13280>,
			<13998 13591 13386 13302 13285 13281>,
			<13963 13597 13389 13302 13286 13282>,
			<13955 13599 13390 13303 13287 13283>,
			<13986 13592 13388 13305 13288 13284>,
			<14021 13584 13386 13307 13289 13286>,
			<13970 13593 13387 13308 13289 13286>,
			<13814 13619 13390 13309 13290 13287>,
			<13722 13625 13391 13310 13291 13288>,
			<13678 13600 13390 13311 13296 13288>,
			<13657 13574 13389 13312 13299 13289>,
			<13676 13557 13396 13312 13298 13290>,
			<13713 13540 13406 13312 13297 13291>,
			<13704 13535 13408 13312 13297 13292>,
			<13596 13534 13406 13314 13299 13292>,
			<13527 13532 13404 13316 13300 13293>,
			<13527 13513 13397 13322 13298 13292>,
			<13528 13485 13389 13327 13296 13291>,
			<13531 13466 13383 13326 13296 13291>,
			<13539 13450 13377 13322 13296 13290>,
			<13542 13436 13371 13317 13296 13289>,
			<13530 13423 13363 13309 13290 13284>,
			<13518 13412 13356 13303 13284 13279>,
			<13523 13405 13353 13302 13284 13279>,
			<13541 13401 13350 13301 13286 13279>,
			<13560 13390 13347 13300 13288 13279>,
			<13579 13365 13344 13301 13294 13278>,
			<13602 13349 13343 13301 13297 13277>,
			<13632 13352 13345 13302 13292 13277>,
			<13668 13360 13346 13304 13286 13278>,
			<13701 13369 13344 13306 13294 13279>,
			<13730 13383 13337 13308 13318 13281>,
			<13764 13398 13334 13309 13326 13282>,
			<13810 13413 13340 13310 13315 13280>,
			<13861 13429 13347 13310 13302 13278>,
			<13914 13447 13354 13309 13296 13277>,
			<13970 13469 13361 13306 13292 13277>,
			<14033 13494 13363 13304 13296 13277>,
			<14111 13525 13360 13302 13318 13277>,
			<14172 13560 13358 13302 13321 13279>,
			<14209 13605 13357 13304 13306 13281>,
			<14238 13649 13348 13302 13282 13278>,
			<14099 13604 13332 13296 13287 13277>,
			<14211 13703 13342 13302 13298 13287>,
			<14306 13779 13348 13303 13298 13286>,
			<14372 13840 13361 13308 13285 13289>,
			<14460 13940 13377 13319 13285 13293>,
			<14548 14035 13392 13325 13283 13291>,
			<14674 14132 13395 13307 13299 13288>,
			<14787 14255 13401 13312 13288 13291>,
			<15137 14441 13440 13326 13303 13295>,
			<15969 14723 13509 13342 13296 13300>,
			<15969 14723 13509 13342 13296 13300>,
			<15969 14723 13509 13342 13296 13300>;
	};

	qcom,pc-temp-y4-lut {
		qcom,lut-col-legend = <(-10) 0 10 25 40 50>;
		qcom,lut-row-legend = <10000 9800 9600 9400 9200 9000>,
			<8800 8600 8400 8200 8000 7800>,
			<7600 7400 7200 7000 6800 6600>,
			<6400 6200 6000 5800 5600 5400>,
			<5200 5000 4800 4600 4400 4200>,
			<4000 3800 3600 3400 3200 3000>,
			<2800 2600 2400 2200 2000 1800>,
			<1600 1400 1200 1000 900 800>,
			<700 600 500 400 300 200>,
			<100 0>;
		qcom,lut-data = <17704 17093 16733 16537 16499 16481>,
			<17783 17107 16728 16537 16494 16476>,
			<17830 17119 16725 16539 16491 16473>,
			<17854 17129 16724 16541 16490 16470>,
			<17862 17134 16725 16544 16490 16470>,
			<17859 17136 16726 16546 16491 16469>,
			<17707 17134 16730 16548 16494 16471>,
			<17537 17129 16735 16552 16497 16474>,
			<17566 17109 16739 16558 16503 16477>,
			<17702 17068 16745 16568 16509 16482>,
			<17833 17059 16752 16578 16514 16487>,
			<17978 17107 16760 16589 16516 16494>,
			<18068 17173 16772 16602 16519 16501>,
			<17854 17265 16809 16621 16530 16509>,
			<17441 17368 16855 16646 16548 16517>,
			<17361 17335 16861 16667 16562 16526>,
			<17449 17063 16846 16686 16572 16536>,
			<17506 16904 16823 16702 16585 16548>,
			<17476 16913 16773 16717 16614 16570>,
			<17413 16923 16716 16728 16639 16590>,
			<17344 16919 16685 16708 16636 16589>,
			<17257 16897 16663 16635 16617 16580>,
			<17192 16875 16649 16580 16589 16565>,
			<17147 16857 16639 16543 16532 16518>,
			<17118 16835 16633 16522 16491 16482>,
			<17108 16790 16631 16523 16493 16482>,
			<17102 16731 16630 16526 16498 16483>,
			<17099 16720 16631 16531 16498 16487>,
			<17098 16748 16633 16538 16489 16499>,
			<17096 16779 16634 16547 16487 16512>,
			<17093 16799 16621 16556 16531 16525>,
			<17090 16816 16604 16567 16583 16537>,
			<17091 16835 16606 16577 16570 16550>,
			<17097 16858 16622 16587 16507 16562>,
			<17102 16874 16636 16591 16484 16566>,
			<17107 16883 16646 16584 16478 16546>,
			<17113 16891 16655 16575 16471 16521>,
			<17126 16901 16667 16565 16462 16505>,
			<17152 16911 16680 16554 16452 16492>,
			<17172 16914 16683 16551 16450 16490>,
			<17192 16905 16682 16557 16456 16496>,
			<17210 16895 16682 16558 16457 16496>,
			<17231 16884 16679 16553 16459 16488>,
			<17206 16863 16665 16545 16576 16486>,
			<17073 16838 16654 16520 16442 16464>,
			<17094 16846 16663 16538 16449 16477>,
			<17115 16869 16683 16563 16491 16497>,
			<17136 16896 16710 16584 16569 16518>,
			<17143 16942 16743 16602 16595 16541>,
			<17156 16972 16764 16607 16641 16529>,
			<17140 16973 16749 16591 16545 16484>,
			<17122 16962 16750 16578 16575 16483>,
			<17255 16979 16811 16579 16545 16491>,
			<17727 17064 16885 16625 16652 16553>,
			<17727 17064 16885 16625 16652 16553>,
			<17727 17064 16885 16625 16652 16553>;
	};

	qcom,pc-temp-y5-lut {
		qcom,lut-col-legend = <(-10) 0 10 25 40 50>;
		qcom,lut-row-legend = <10000 9800 9600 9400 9200 9000>,
			<8800 8600 8400 8200 8000 7800>,
			<7600 7400 7200 7000 6800 6600>,
			<6400 6200 6000 5800 5600 5400>,
			<5200 5000 4800 4600 4400 4200>,
			<4000 3800 3600 3400 3200 3000>,
			<2800 2600 2400 2200 2000 1800>,
			<1600 1400 1200 1000 900 800>,
			<700 600 500 400 300 200>,
			<100 0>;
		qcom,lut-data = <12068 11009 12779 14361 14331 15769>,
			<11514 11386 13184 14205 14631 16171>,
			<11276 11911 13559 14017 14790 16427>,
			<11290 12459 13866 13830 14846 16560>,
			<11494 12901 14067 13682 14834 16593>,
			<11856 13114 14118 13608 14788 16548>,
			<13331 13176 13916 13600 14636 16384>,
			<14796 13240 13681 13566 14409 16138>,
			<14172 13851 13652 13415 14111 15842>,
			<12189 15226 13697 13220 13757 15455>,
			<11545 15547 13701 13148 13717 15050>,
			<12220 14282 13648 13043 14193 14579>,
			<13395 13251 13635 12956 14554 14203>,
			<16005 14263 13780 12748 14111 14025>,
			<19492 16342 14121 12397 13376 13957>,
			<19438 17493 15009 12365 13260 13913>,
			<14529 18357 17334 12652 13322 13689>,
			<11377 18703 18511 13140 13358 13497>,
			<11557 17526 18186 14622 13294 13320>,
			<11882 15954 17788 16599 13221 13170>,
			<12140 15589 17722 18131 14212 13802>,
			<12390 15470 17592 19617 16962 15750>,
			<12465 15471 17312 19962 17865 16640>,
			<12056 15815 16470 18040 17214 16718>,
			<11578 16160 15725 16115 16499 16616>,
			<11456 16153 15498 15693 16143 16322>,
			<11394 15951 15356 15467 15888 15839>,
			<11380 15351 15366 15303 16090 15251>,
			<11385 13418 15491 15231 17462 14409>,
			<11394 12110 15671 15324 18223 13977>,
			<11438 12006 16214 15660 16861 14085>,
			<11509 11949 16812 16159 15280 14312>,
			<11511 11907 16423 16826 36802 14749>,
			<11435 11885 14907 17776 65535 15635>,
			<11372 11900 14300 18445 65535 16026>,
			<11385 12029 14707 18862 65535 15988>,
			<11420 12180 15316 19111 65535 15927>,
			<11387 12278 16007 18667 65535 15841>,
			<11277 12413 16782 17251 65535 15602>,
			<11246 12498 16845 16207 65535 15321>,
			<11411 12603 16012 15184 65535 14678>,
			<11482 12515 15466 14958 65535 14675>,
			<11540 12138 15034 15061 45359 15171>,
			<11760 12122 13939 14756 46801 15113>,
			<11835 11825 12682 14114 47483 15141>,
			<11704 11924 13035 14158 65535 15921>,
			<11789 11941 13058 13555 65535 14475>,
			<11814 12072 13338 13680 14894 14156>,
			<12168 12117 13969 14265 14425 14815>,
			<12133 12539 14652 14829 14238 14829>,
			<12410 12621 14707 13009 24866 15109>,
			<12097 12141 13847 13745 19747 16314>,
			<11215 12119 12752 15324 21080 17428>,
			<10519 12039 12693 17888 19107 19756>,
			<10519 12039 12693 17888 19107 19756>,
			<10519 12039 12693 17888 19107 19756>;
	};

	qcom,pc-temp-y6-lut {
		qcom,lut-col-legend = <(-10) 0 10 25 40 50>;
		qcom,lut-row-legend = <10000 9800 9600 9400 9200 9000>,
			<8800 8600 8400 8200 8000 7800>,
			<7600 7400 7200 7000 6800 6600>,
			<6400 6200 6000 5800 5600 5400>,
			<5200 5000 4800 4600 4400 4200>,
			<4000 3800 3600 3400 3200 3000>,
			<2800 2600 2400 2200 2000 1800>,
			<1600 1400 1200 1000 900 800>,
			<700 600 500 400 300 200>,
			<100 0>;
		qcom,lut-data = <6738 5700 5251 5018 4962 4941>,
			<6720 5717 5251 5017 4960 4941>,
			<6698 5728 5251 5017 4960 4940>,
			<6675 5732 5249 5017 4960 4940>,
			<6653 5734 5247 5017 4960 4941>,
			<6636 5732 5245 5018 4961 4942>,
			<6622 5719 5242 5019 4962 4943>,
			<6607 5704 5238 5021 4964 4944>,
			<6572 5704 5236 5023 4966 4945>,
			<6516 5706 5235 5026 4967 4947>,
			<6499 5706 5235 5029 4969 4950>,
			<6511 5699 5235 5033 4972 4952>,
			<6521 5693 5236 5037 4976 4954>,
			<6492 5705 5248 5042 4979 4957>,
			<6422 5726 5267 5048 4983 4960>,
			<6360 5717 5270 5054 4987 4963>,
			<6298 5646 5265 5060 4991 4966>,
			<6260 5596 5257 5067 4995 4970>,
			<6248 5586 5238 5075 5002 4976>,
			<6240 5580 5215 5081 5007 4981>,
			<6233 5574 5203 5075 5006 4981>,
			<6225 5569 5194 5052 5000 4977>,
			<6218 5564 5186 5033 4991 4971>,
			<6208 5559 5179 5016 4970 4954>,
			<6201 5553 5175 5006 4955 4940>,
			<6209 5545 5174 5006 4957 4940>,
			<6234 5537 5173 5007 4960 4941>,
			<6254 5536 5173 5009 4962 4941>,
			<6271 5544 5175 5012 4965 4944>,
			<6288 5558 5177 5015 4968 4948>,
			<6313 5579 5179 5019 4977 4951>,
			<6345 5610 5183 5024 4987 4956>,
			<6373 5642 5187 5029 4989 4960>,
			<6396 5678 5191 5035 4987 4966>,
			<6423 5712 5197 5037 4985 4967>,
			<6462 5742 5209 5036 4981 4961>,
			<6506 5774 5224 5035 4976 4952>,
			<6553 5813 5241 5033 4971 4948>,
			<6604 5858 5260 5029 4967 4944>,
			<6659 5899 5274 5028 4968 4943>,
			<6725 5934 5285 5029 4979 4946>,
			<6778 5976 5298 5030 4980 4947>,
			<6816 6031 5311 5031 4975 4946>,
			<6829 6070 5312 5029 4995 4944>,
			<6698 6030 5295 5017 4966 4937>,
			<6791 6118 5337 5029 4975 4948>,
			<6876 6197 5364 5037 4986 4954>,
			<6933 6252 5399 5049 5005 4961>,
			<6997 6347 5435 5062 5015 4971>,
			<7077 6432 5471 5067 5026 4967>,
			<7170 6516 5497 5052 5003 4952>,
			<7272 6614 5540 5054 5009 4953>,
			<7637 6777 5625 5069 5011 4960>,
			<8526 7040 5743 5097 5041 4983>,
			<8526 7040 5743 5097 5041 4983>,
			<8526 7040 5743 5097 5041 4983>;
	};

};
